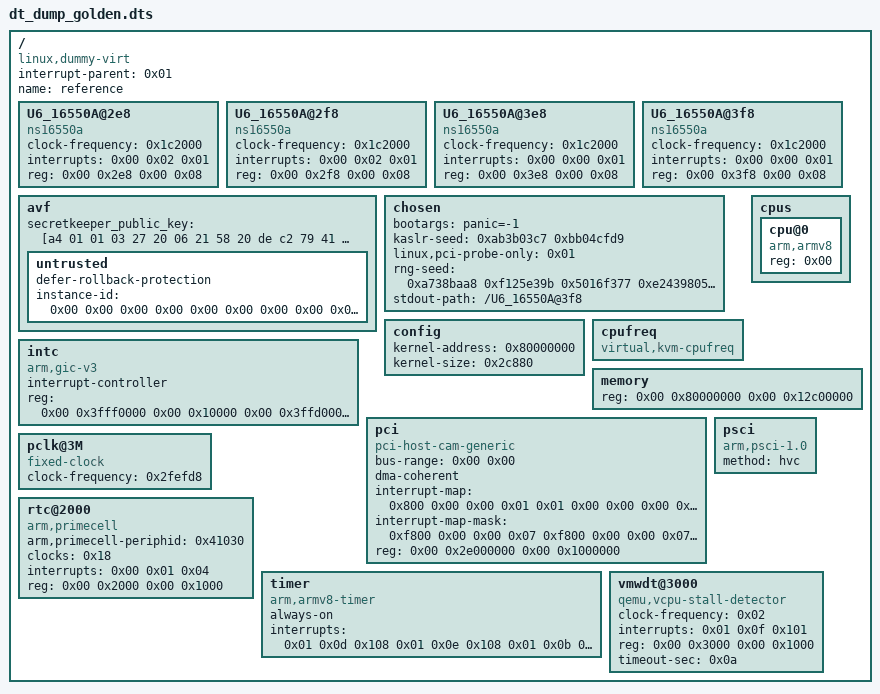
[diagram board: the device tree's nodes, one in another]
/dts-v1/;

/ {
	#address-cells = <0x02>;
	#size-cells = <0x02>;
	compatible = "linux,dummy-virt";
	interrupt-parent = <0x01>;
	name = "reference";

	U6_16550A@2e8 {
		clock-frequency = <0x1c2000>;
		compatible = "ns16550a";
		interrupts = <0x00 0x02 0x01>;
		reg = <0x00 0x2e8 0x00 0x08>;
	};

	U6_16550A@2f8 {
		clock-frequency = <0x1c2000>;
		compatible = "ns16550a";
		interrupts = <0x00 0x02 0x01>;
		reg = <0x00 0x2f8 0x00 0x08>;
	};

	U6_16550A@3e8 {
		clock-frequency = <0x1c2000>;
		compatible = "ns16550a";
		interrupts = <0x00 0x00 0x01>;
		reg = <0x00 0x3e8 0x00 0x08>;
	};

	U6_16550A@3f8 {
		clock-frequency = <0x1c2000>;
		compatible = "ns16550a";
		interrupts = <0x00 0x00 0x01>;
		reg = <0x00 0x3f8 0x00 0x08>;
	};

	__symbols__ {
		intc = "/intc";
	};

	avf {
		secretkeeper_public_key = [a4 01 01 03 27 20 06 21 58 20 de c2 79 41 b5 2a d8 1e eb dd 8a c5 a0 2f e4 56 12 42 5e b5 a4 c6 6a 8c 32 81 65 75 1c 6e b2 87];

		untrusted {
			defer-rollback-protection;
			instance-id = <0x00 0x00 0x00 0x00 0x00 0x00 0x00 0x00 0x00 0x00 0x00 0x00 0x00 0x00 0x00 0x00>;
		};
	};

	chosen {
		bootargs = "panic=-1";
		kaslr-seed = <0xab3b03c7 0xbb04cfd9>;
		linux,pci-probe-only = <0x01>;
		rng-seed = <0xa738baa8 0xf125e39b 0x5016f377 0xe2439805 0x94624c7e 0xac404bf6 0x68ece261 0xd45cca77 0x72328c0d 0xfdb9674f 0x74c1eb50 0x5665af83 0x1e8ccb52 0x120ed001 0xdc057599 0xbb3d33ea 0x6f9eb8e7 0x44f0517e 0x65d1cd16 0xeb4506a7 0x63fe5a00 0x8e330a52 0x2ab37c64 0x9aec3871 0x80f24353 0xfcdea704 0xd0e4fa1b 0x86412d49 0xed12a31d 0x1fbe26f3 0x97e442c5 0x25b31828 0xbe8626eb 0xea8098b8 0x6bf93ad9 0x3676d94a 0xcdbf695a 0x8b68008c 0xf598963b 0x483d0817 0xcea64b84 0xbbe0d7af 0xb09d31d7 0xfa461596 0xc47f9be8 0xd992c480 0x98372ef6 0xe1e70464 0xdc2752e4 0xe40a042c 0x5bb3a936 0x8af0aaff 0xd52f6723 0x8ac81a1b 0x15ed83d 0xee00b9eb 0x107f8ce 0xda99d512 0xed26543c 0x959f76f 0x1b85d5dc 0xa0b36c99 0xcdc8351 0xa4196327>;
		stdout-path = "/U6_16550A@3f8";
	};

	config {
		kernel-address = <0x80000000>;
		kernel-size = <0x2c880>;
	};

	cpufreq {
		compatible = "virtual,kvm-cpufreq";
	};

	cpus {
		#address-cells = <0x01>;
		#size-cells = <0x00>;

		cpu@0 {
			compatible = "arm,armv8";
			device_type = "cpu";
			phandle = <0x100>;
			reg = <0x00>;
		};
	};

	intc {
		#address-cells = <0x02>;
		#interrupt-cells = <0x03>;
		#size-cells = <0x02>;
		compatible = "arm,gic-v3";
		interrupt-controller;
		phandle = <0x01>;
		reg = <0x00 0x3fff0000 0x00 0x10000 0x00 0x3ffd0000 0x00 0x20000>;
	};

	memory {
		device_type = "memory";
		reg = <0x00 0x80000000 0x00 0x12c00000>;
	};

	pci {
		#address-cells = <0x03>;
		#interrupt-cells = <0x01>;
		#size-cells = <0x02>;
		bus-range = <0x00 0x00>;
		compatible = "pci-host-cam-generic";
		device_type = "pci";
		dma-coherent;
		interrupt-map = <0x800 0x00 0x00 0x01 0x01 0x00 0x00 0x00 0x04 0x04 0x1000 0x00 0x00 0x01 0x01 0x00 0x00 0x00 0x05 0x04 0x1800 0x00 0x00 0x01 0x01 0x00 0x00 0x00 0x06 0x04 0x2000 0x00 0x00 0x01 0x01 0x00 0x00 0x00 0x07 0x04 0x2800 0x00 0x00 0x01 0x01 0x00 0x00 0x00 0x08 0x04 0x3000 0x00 0x00 0x01 0x01 0x00 0x00 0x00 0x09 0x04 0x3800 0x00 0x00 0x01 0x01 0x00 0x00 0x00 0x0a 0x04 0x4000 0x00 0x00 0x01 0x01 0x00 0x00 0x00 0x0b 0x04>;
		interrupt-map-mask = <0xf800 0x00 0x00 0x07 0xf800 0x00 0x00 0x07 0xf800 0x00 0x00 0x07 0xf800 0x00 0x00 0x07 0xf800 0x00 0x00 0x07 0xf800 0x00 0x00 0x07 0xf800 0x00 0x00 0x07 0xf800 0x00 0x00 0x07>;
		ranges = <0x3000000 0x00 0x2c000000 0x00 0x2c000000 0x00 0x2000000 0x43000000 0x00 0x93400000 0x00 0x93400000 0xff 0x6cc00000>;
		reg = <0x00 0x2e000000 0x00 0x1000000>;
	};

	pclk@3M {
		#clock-cells = <0x00>;
		clock-frequency = <0x2fefd8>;
		compatible = "fixed-clock";
		phandle = <0x18>;
	};

	psci {
		compatible = "arm,psci-1.0\0arm,psci-0.2";
		method = "hvc";
	};

	rtc@2000 {
		arm,primecell-periphid = <0x41030>;
		clock-names = "apb_pclk";
		clocks = <0x18>;
		compatible = "arm,primecell";
		interrupts = <0x00 0x01 0x04>;
		reg = <0x00 0x2000 0x00 0x1000>;
	};

	timer {
		always-on;
		compatible = "arm,armv8-timer";
		interrupts = <0x01 0x0d 0x108 0x01 0x0e 0x108 0x01 0x0b 0x108 0x01 0x0a 0x108>;
	};

	vmwdt@3000 {
		clock-frequency = <0x02>;
		compatible = "qemu,vcpu-stall-detector";
		interrupts = <0x01 0x0f 0x101>;
		reg = <0x00 0x3000 0x00 0x1000>;
		timeout-sec = <0x0a>;
	};
};
